# ms_ti_tcp2_rl_edma_bus_011 register map
Vendor: Texas Instruments
Peripheral module from a debugger description file (folder TCI6484_C6457).
Registers are 32-bit, access not given, reset 0x0 unless marked. A register's access mark holds for its fields unless they carry their own. Offsets are as the file gives them; lines under a group give offsets from that group; [hi:lo] are bit positions; {n}, {i} and the like mark numbered series; 'fields as' and 'values as' point back to an identical list; <NAME> marks a mode.

## TCP2 — Turbo-decoder Coprocessor (TCP) has designed to meet requirement of high bit rate data decoding as in IS2000 and 3GPP wireless standards.TCP provides very low processing delay because of the highly paralleled architechure. Processing delay can be further reduced by enabling stopping criteria algorithm. TCP reduces board space and power consumption by performing turbo decoding on-chip. TCP is high flexibility to cope with standard evolutions. Accepts any frame length from 40 (3GPP minimum frame size) up to 20730 (IS2000 maximum frame size).
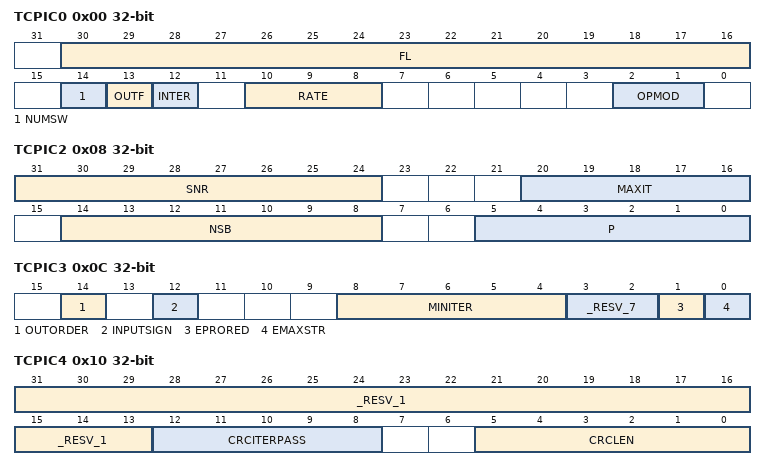
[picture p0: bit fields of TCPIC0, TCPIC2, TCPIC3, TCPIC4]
0x00 TCPIC0 — TCPIC0 used to configure TCP
  [30:16] FL rw — Frame Length. Number of symbols in the frame to be decoded
  [14] NUMSW rw — Number of slide window per subblock
    0=LEQ_128 (Block size <=128); 1=G_128 (Block size >128)
  [13] OUTF rw — Output parameters read flag (SA mode only; in SP mode, must be cleared to 0).
    0=NO (No REVT generation. Output parameters are not read via EDMA); 1=YES (REVT generation. Output parameters are read via EDMA.)
  [12] INTER rw — Interleaver write flag
    0=NO (Interleaver table is not sent to the TCP (required for SP mode)); 1=YES (Interleaver table is sent to the TCP (required for SA mode))
  [10:8] RATE rw — Code rate
    1=3_4 (Rate 3/4); {v}=1_{v} (Rate 1/{v}) (v=2..5)
  [2:1] OPMOD rw — Operational mode
    0=SA (Stand alone mode); 1=SP_FF (SP mode first sub frame); 2=SP_MF (SP mode middle sub frame); 3=SP_LF (SP mode last sub frame)
0x04 TCPIC1 — TCPIC1 is used to configure the TCP
  [22:16] R rw — Reliability length - 1 (from 39 to 127). Number of symbols - 1 to be used in the reliability portion of a frame or subframe.
0x08 TCPIC2 — TCPIC2 is used to configure the TCP
  [31:24] SNR rw — SNR threshold (from 0 to 100) (SA mode only; don't care in SP mode)
    0=DISABLE (Disable SNR ratio threshold)
  [20:16] MAXIT rw — Maximum number of iterations (from 0 to 32) (SA mode only; don't care in SP mode)
  [14:8] NSB rw — Number of subblocks
  [5:0] P rw — Prolog size, minimum 4 and maximum 48
0x0C TCPIC3 — TCPIC3 is used to configure the TCP
  [14] OUTORDER rw
    0=0_31 (Output bit ordering form 0 to 31); 1=31_0 (Output bit ordering from 31 to 0)
  [12] INPUTSIGN rw
    0=POSITIVE (Multiply channel input data by +1); 1=NEGATIVE (Multiply channel input data by -1)
  [8:4] MINITER rw — Minimum number of iterations
  [3:2] _RESV_7 — (access N)
  [1] EPRORED rw — Prolog reduction
    0=DISABLE (Prolog reduction disable); 1=ENABLE (Prolog reduction enable)
  [0] EMAXSTR rw — Max star
    0=DISABLE (Max star disable); 1=ENABLE (Max star enable)
0x10 TCPIC4 — TCPIC4 is used to set CRC configuration
  [31:13] _RESV_1 — (access N)
  [12:8] CRCITERPASS rw — Number of CRC iterations passed iterations required before decoder termination
  [5:0] CRCLEN rw — CRC length
    0=DISABLE
0x14 TCPIC5 rw — TCPIC5 defines the CRC polynomial
  [31:0] CRCPOLY — CRC Polynomial
0x18 TCPIC6 — TCPIC6 is used to set the tail bits used by the TCP
  [17:0] TAIL1 rw — Tail bits
{0x0+4i} TCPIC{i} (i=7..11) — TCPIC{i} is used to set the tail bits used by the TCP.
  [17:0] TAIL{i-5} rw — Tail bits{i-5}
{0x0+4i} TCPIC{i} (i=12..15) — Extrinsic scale factor
  [23:0] EXT_SCALE_{4i-48}_{4i-45} rw
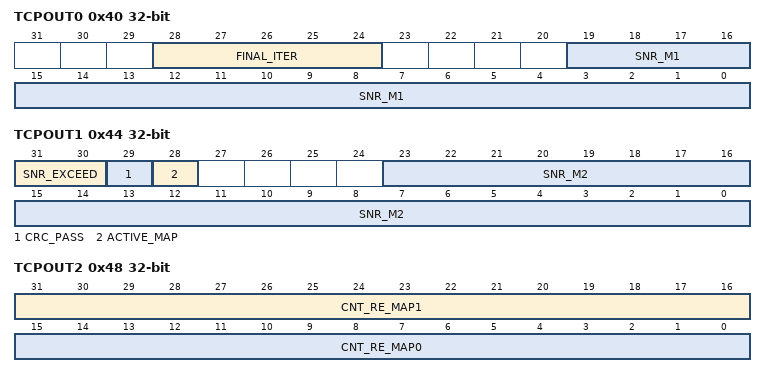
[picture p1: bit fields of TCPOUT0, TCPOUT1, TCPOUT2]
0x40 TCPOUT0 — TCPOUT0 is output parameter register 0
  [28:24] FINAL_ITER rw — Number of decoded iterations
  [19:0] SNR_M1 rw — First moment of SNR calculations
0x44 TCPOUT1 — TCPOUT1 is output parameter register 1
  [31:30] SNR_EXCEED rw — SNR pass decoder termination reason
    0=MAP01_FAIL (MAP0/MAP1 failed SNR); 1=MAP01_PASS (MAP0/1 passed SNR)
  [29] CRC_PASS rw
    0=NO (CRC check not passed); 1=YES (CRC check passed)
  [28] ACTIVE_MAP rw
    0=MAP0 (MAP0 is active); 1=MAP1 (MAP1 is active)
  [23:0] SNR_M2 rw — Second moment of SNR calculation
0x48 TCPOUT2 rw — TCPOUT2 is output parameter register 2
  [31:16] CNT_RE_MAP1 — No of MAP1 re-encode errors
  [15:0] CNT_RE_MAP0 — No of MAP0 re-encode errors
